# STM32WLE4C8U6 register map
File version: 1.0
Registers are 32-bit, access not given, reset 0x0 unless marked. A register's access mark holds for its fields unless they carry their own. Offsets are from the block's base; [hi:lo] are bit positions; {n}, {i} and the like mark numbered series.

## EXTI
Base 0x58000800
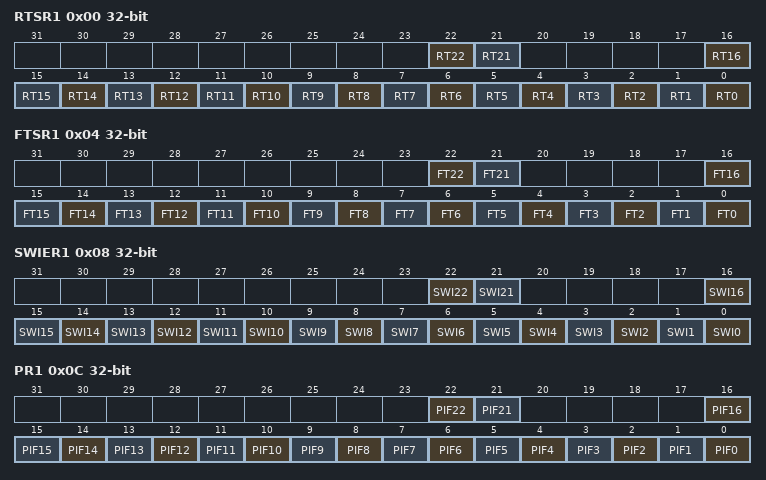
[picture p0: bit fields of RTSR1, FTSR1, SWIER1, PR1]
0x00 RTSR1
  [22] RT22, [21] RT21, [n] RT{n} (n=0..16)
0x04 FTSR1
  [22] FT22, [21] FT21, [n] FT{n} (n=0..16)
0x08 SWIER1
  [22] SWI22, [21] SWI21, [n] SWI{n} (n=0..16)
0x0C PR1
  [22] PIF22, [21] PIF21, [n] PIF{n} (n=0..16)
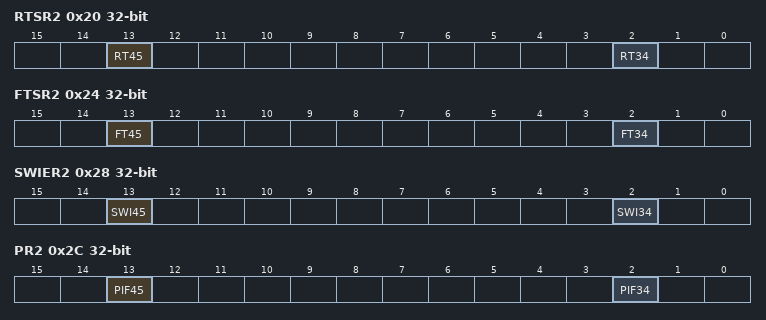
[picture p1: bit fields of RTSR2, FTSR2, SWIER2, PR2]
0x20 RTSR2
  [13] RT45, [2] RT34
0x24 FTSR2
  [13] FT45, [2] FT34
0x28 SWIER2
  [13] SWI45, [2] SWI34
0x2C PR2
  [13] PIF45, [2] PIF34
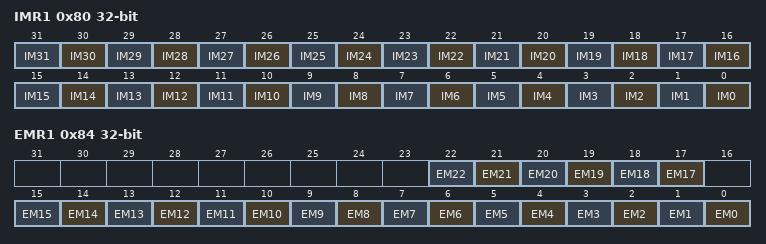
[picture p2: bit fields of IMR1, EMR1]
0x80 IMR1
  [n] IM{n} (n=0..31)
0x84 EMR1
  [n] EM{n} (n=17..22), [n] EM{n} (n=0..15)
0x90 IMR2
  [13] IM45, [12] IM44, [14:11] IM46, [10] IM42, [6] IM38, [2] IM34

## TRNG
Base 0x58001000
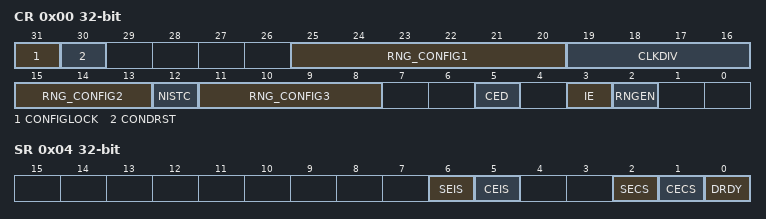
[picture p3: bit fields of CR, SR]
0x00 CR
  [31] CONFIGLOCK, [30] CONDRST, [25:20] RNG_CONFIG1, [19:16] CLKDIV, [15:13] RNG_CONFIG2, [12] NISTC, [11:8] RNG_CONFIG3, [5] CED, [3] IE, [2] RNGEN
0x04 SR
  [6] SEIS, [5] CEIS, [2] SECS, [1] CECS, [0] DRDY
0x08 DR
  [31:0] RNDATA
0x10 HTCR
  [31:0] HTCFG

## HSEM
Base 0x58001400
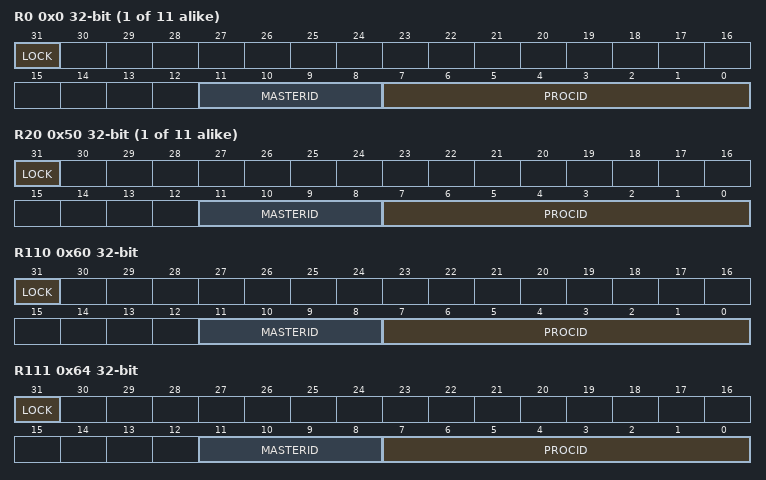
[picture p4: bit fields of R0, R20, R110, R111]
{0x0+4i} R{i} (i=0..10)
  [31] LOCK, [11:8] MASTERID, [7:0] PROCID
{0x0+4i} R{i} (i=20..30)
  [31] LOCK, [11:8] MASTERID, [7:0] PROCID
0x60 R110
  [31] LOCK, [11:8] MASTERID, [7:0] PROCID
0x64 R111
  [31] LOCK, [11:8] MASTERID, [7:0] PROCID
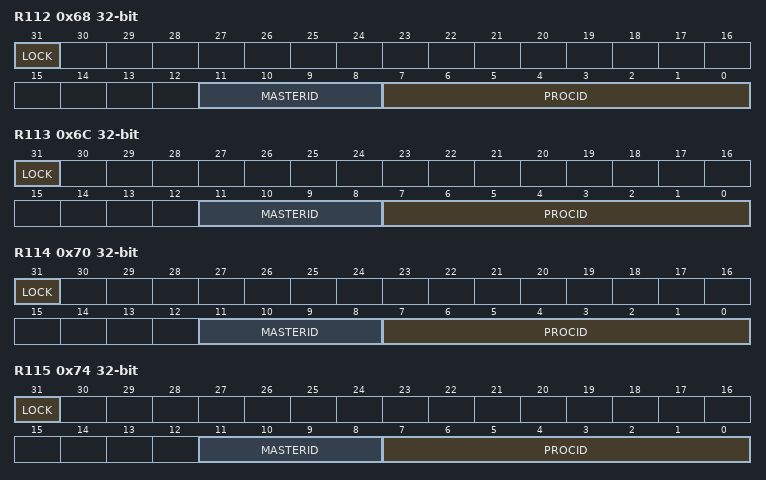
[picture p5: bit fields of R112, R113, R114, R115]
0x68 R112
  [31] LOCK, [11:8] MASTERID, [7:0] PROCID
0x6C R113
  [31] LOCK, [11:8] MASTERID, [7:0] PROCID
0x70 R114
  [31] LOCK, [11:8] MASTERID, [7:0] PROCID
0x74 R115
  [31] LOCK, [11:8] MASTERID, [7:0] PROCID
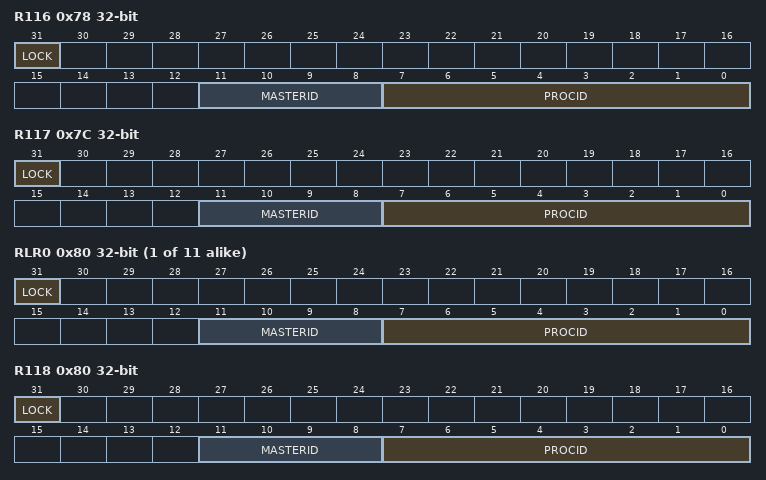
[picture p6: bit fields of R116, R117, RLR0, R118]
0x78 R116
  [31] LOCK, [11:8] MASTERID, [7:0] PROCID
0x7C R117
  [31] LOCK, [11:8] MASTERID, [7:0] PROCID
{0x80+4i} RLR{i} (i=0..10)
  [31] LOCK, [11:8] MASTERID, [7:0] PROCID
0x80 R118
  [31] LOCK, [11:8] MASTERID, [7:0] PROCID
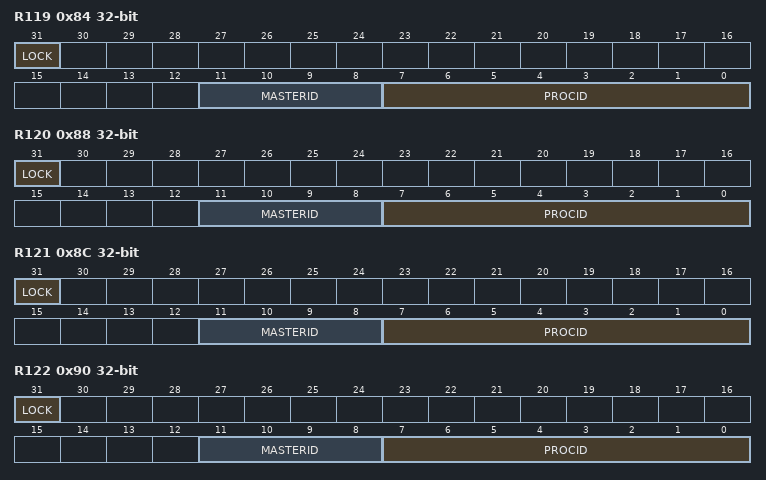
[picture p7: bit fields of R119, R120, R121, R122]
0x84 R119
  [31] LOCK, [11:8] MASTERID, [7:0] PROCID
0x88 R120
  [31] LOCK, [11:8] MASTERID, [7:0] PROCID
0x8C R121
  [31] LOCK, [11:8] MASTERID, [7:0] PROCID
0x90 R122
  [31] LOCK, [11:8] MASTERID, [7:0] PROCID
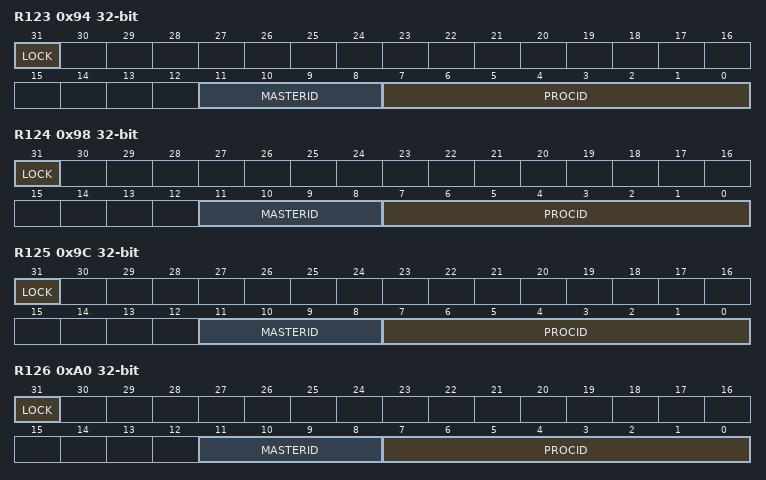
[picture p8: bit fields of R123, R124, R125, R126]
0x94 R123
  [31] LOCK, [11:8] MASTERID, [7:0] PROCID
0x98 R124
  [31] LOCK, [11:8] MASTERID, [7:0] PROCID
0x9C R125
  [31] LOCK, [11:8] MASTERID, [7:0] PROCID
0xA0 R126
  [31] LOCK, [11:8] MASTERID, [7:0] PROCID
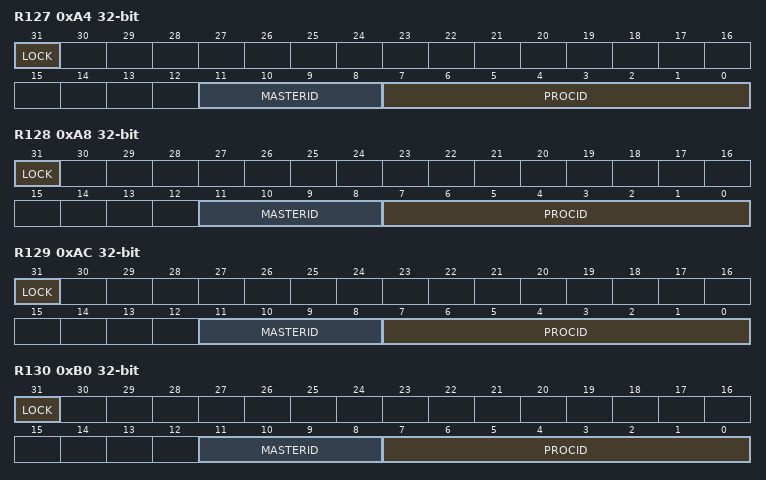
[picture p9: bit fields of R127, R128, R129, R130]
0xA4 R127
  [31] LOCK, [11:8] MASTERID, [7:0] PROCID
0xA8 R128
  [31] LOCK, [11:8] MASTERID, [7:0] PROCID
0xAC R129
  [31] LOCK, [11:8] MASTERID, [7:0] PROCID
0xB0 R130
  [31] LOCK, [11:8] MASTERID, [7:0] PROCID
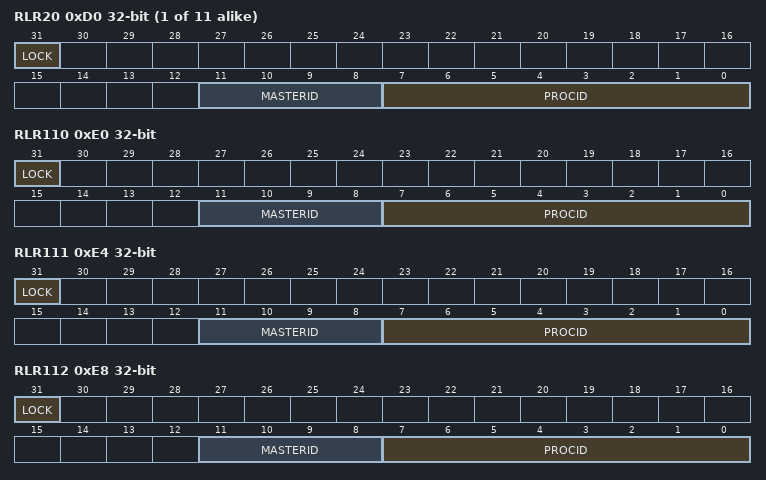
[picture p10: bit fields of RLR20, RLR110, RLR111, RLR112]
{0x80+4i} RLR{i} (i=20..30)
  [31] LOCK, [11:8] MASTERID, [7:0] PROCID
0xE0 RLR110
  [31] LOCK, [11:8] MASTERID, [7:0] PROCID
0xE4 RLR111
  [31] LOCK, [11:8] MASTERID, [7:0] PROCID
0xE8 RLR112
  [31] LOCK, [11:8] MASTERID, [7:0] PROCID
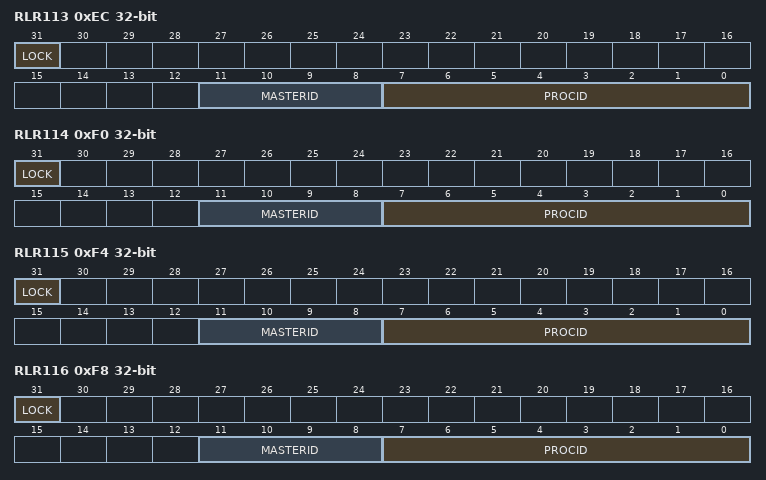
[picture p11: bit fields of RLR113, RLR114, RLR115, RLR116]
0xEC RLR113
  [31] LOCK, [11:8] MASTERID, [7:0] PROCID
0xF0 RLR114
  [31] LOCK, [11:8] MASTERID, [7:0] PROCID
0xF4 RLR115
  [31] LOCK, [11:8] MASTERID, [7:0] PROCID
0xF8 RLR116
  [31] LOCK, [11:8] MASTERID, [7:0] PROCID
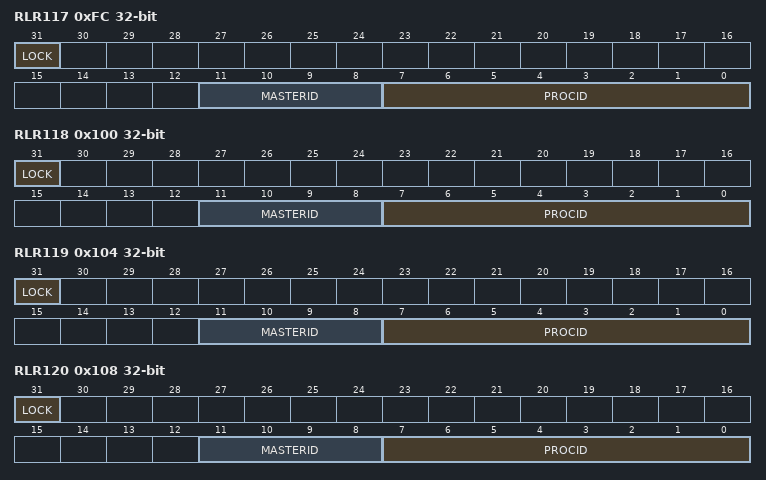
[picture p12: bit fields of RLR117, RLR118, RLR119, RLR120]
0xFC RLR117
  [31] LOCK, [11:8] MASTERID, [7:0] PROCID
0x100 IER
  [15:0] ISE
0x100 RLR118
  [31] LOCK, [11:8] MASTERID, [7:0] PROCID
0x104 ICR
  [15:0] ISC
0x104 RLR119
  [31] LOCK, [11:8] MASTERID, [7:0] PROCID
0x108 ISR
  [15:0] ISF
0x108 RLR120
  [31] LOCK, [11:8] MASTERID, [7:0] PROCID
0x10C MISR
  [15:0] MISF
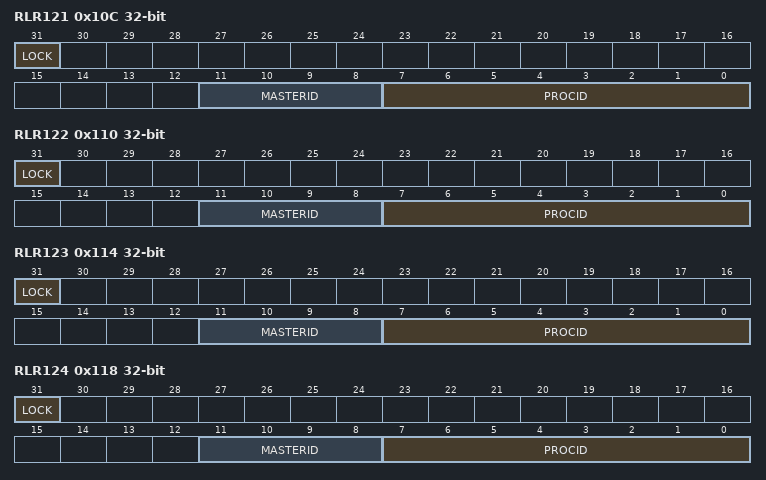
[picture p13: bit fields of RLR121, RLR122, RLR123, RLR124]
0x10C RLR121
  [31] LOCK, [11:8] MASTERID, [7:0] PROCID
0x110 RLR122
  [31] LOCK, [11:8] MASTERID, [7:0] PROCID
0x114 RLR123
  [31] LOCK, [11:8] MASTERID, [7:0] PROCID
0x118 RLR124
  [31] LOCK, [11:8] MASTERID, [7:0] PROCID
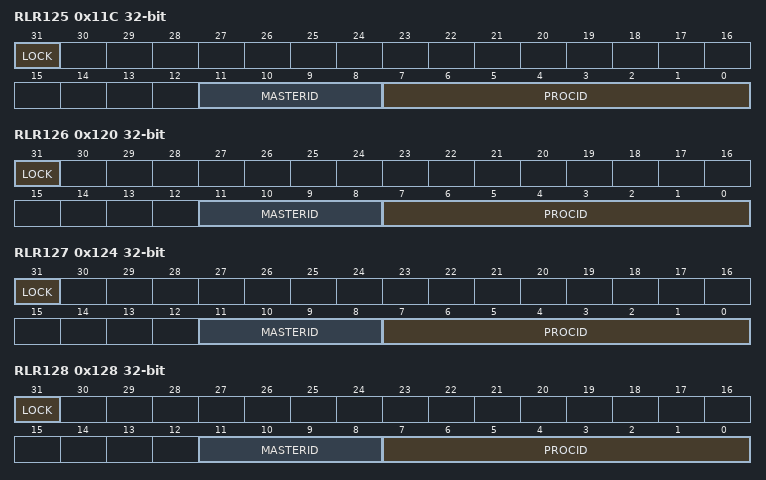
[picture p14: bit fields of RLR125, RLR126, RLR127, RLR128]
0x11C RLR125
  [31] LOCK, [11:8] MASTERID, [7:0] PROCID
0x120 RLR126
  [31] LOCK, [11:8] MASTERID, [7:0] PROCID
0x124 RLR127
  [31] LOCK, [11:8] MASTERID, [7:0] PROCID
0x128 RLR128
  [31] LOCK, [11:8] MASTERID, [7:0] PROCID
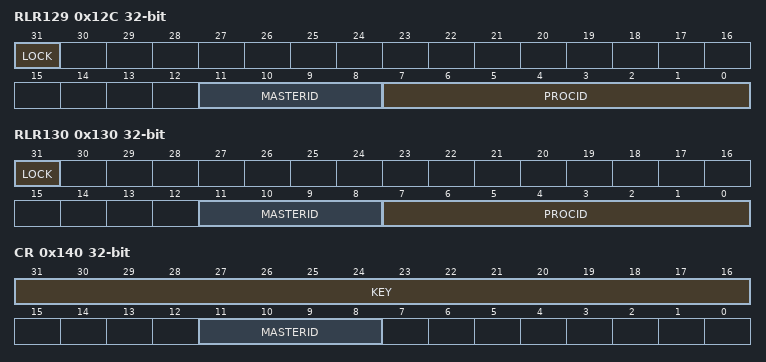
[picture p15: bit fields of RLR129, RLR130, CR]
0x12C RLR129
  [31] LOCK, [11:8] MASTERID, [7:0] PROCID
0x130 RLR130
  [31] LOCK, [11:8] MASTERID, [7:0] PROCID
0x140 CR
  [31:16] KEY, [11:8] MASTERID
0x144 KEYR
  [31:16] KEY

## AES
Base 0x58001800
0x00 CR
  [23:20] NPBLB, [18] KEYSIZE, [14:13] GCMPH, [12] DMAOUTEN, [11] DMAINEN, [10] ERRIE, [9] CCFIE, [8] ERRC, [7] CCFC, [16:5] CHMOD, [4:3] MODE, [2:1] DATATYPE, [0] EN
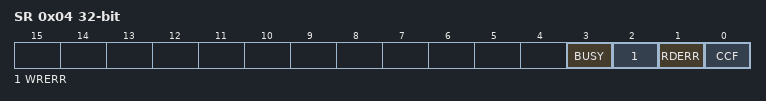
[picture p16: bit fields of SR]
0x04 SR
  [3] BUSY, [2] WRERR, [1] RDERR, [0] CCF
0x08 DINR
  [31:0] DIN
0x0C DOUTR
  [31:0] DOUT
{0x10+4i} KEYR{i} (i=0..3)
  [31:0] KEY
{0x20+4i} IVR{i} (i=0..3)
  [31:0] IVI
{0x20+4i} KEYR{i} (i=4..7)
  [31:0] KEY
{0x40+4i} SUSP{i}R (i=0..7)
  [31:0] SUSP

## PKA
Base 0x58002000
Same registers: PKARAM 0x58002400, PKARAM 0x58002400, PKA 0x58003400, PKA 0x58003400
0x00 CR
  [20] ADDRERRIE, [19] RAMERRIE, [17] PROCENDIE, [13:8] MODE, [1] START, [0] EN
0x04 SR
  [20] ADDRERRF, [19] RAMERRF, [17] PROCENDF, [16] BUSY
0x08 CLRFR
  [20] ADDRERRFC, [19] RAMERRFC, [17] PROCENDFC

## SUBGHZSPI
Base 0x58010000
0x6AC GBSYNCR
  [6] SBITSYNCEN, [5] RXDINV, [4] BITSYNCDIS
0x6B8 GPKTCTL1AR
  [5] SYNCDETEN, [4] CONTTX, [3:2] INFSQEQSEL, [1] INFSSQEQEN, [0] WHITEINI
0x6B9 GWHITEINIRL
  [7:0] WHITEINI
0x6BC GCRCINIRH
  [7:0] CRCINI
0x6BD GCRCINIRL
  [7:0] CRCINI
0x6BE GCRCPOLRH
  [7:0] CRCPOL
0x6BF GCRCPOLRL
  [7:0] CRCPOL
{0x6C0+i} GSYNCR{i} (i=0..7)
  [7:0] SYNCWORD
0x740 LSYNCRH
  [7:0] SYNCWORD
0x741 LSYNCRL
  [7:0] SYNCWORD
0x819 RNGR3
  [7:0] RNDATA
0x81A RNGR2
  [7:0] RNDATA
0x81B RNGR1
  [7:0] RNDATA
0x81C RNGR0
  [7:0] RNDATA
0x89B AGCRSSIC0R
  [6] MODE, [5] MC, [4:2] LENGTH
0x8AC RXGAINCR
  [7:2] SENSI_ADJUST, [1:0] PMODE
0x8E7 PAOCPR
  [5:0] OCP
0x911 HSEINTRIMR
  [5:0] TRIM
0x912 HSEOUTTRIMR
  [5:0] TRIM
0x916 SMPSC0R
  [6] CLKDE
0x91A PCR
  [6] CLE, [5:4] CLV
0x91F REGDRVTSTR
  [3:1] TRIM, [0] EN
0x923 SMPSC2R
  [2:1] DRV
